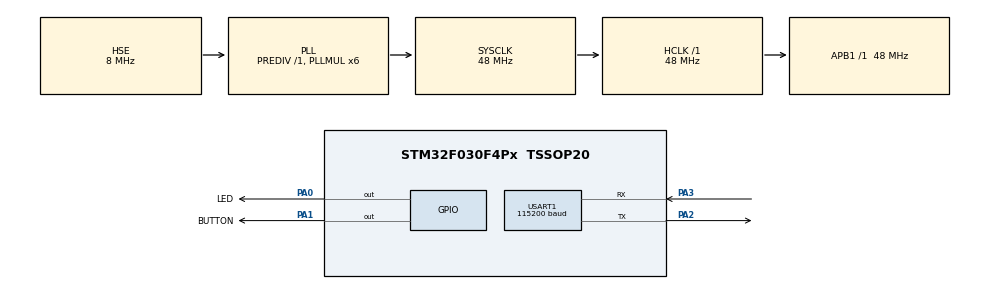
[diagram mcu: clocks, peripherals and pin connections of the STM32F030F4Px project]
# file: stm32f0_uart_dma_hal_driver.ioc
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Dma.Request0=USART1_TX
Dma.Request1=USART1_RX
Dma.USART1_RX.1.Direction=DMA_PERIPH_TO_MEMORY
Dma.USART1_RX.1.Instance=DMA1_Channel3
Dma.USART1_RX.1.MemDataAlignment=DMA_MDATAALIGN_BYTE
Dma.USART1_RX.1.MemInc=DMA_MINC_ENABLE
Dma.USART1_RX.1.Mode=DMA_NORMAL
Dma.USART1_RX.1.PeriphDataAlignment=DMA_PDATAALIGN_BYTE
Dma.USART1_RX.1.PeriphInc=DMA_PINC_DISABLE
Dma.USART1_RX.1.Priority=DMA_PRIORITY_LOW
Dma.USART1_TX.0.Direction=DMA_MEMORY_TO_PERIPH
Dma.USART1_TX.0.Instance=DMA1_Channel2
Dma.USART1_TX.0.MemDataAlignment=DMA_MDATAALIGN_BYTE
Dma.USART1_TX.0.MemInc=DMA_MINC_ENABLE
Dma.USART1_TX.0.Mode=DMA_NORMAL
Dma.USART1_TX.0.PeriphDataAlignment=DMA_PDATAALIGN_BYTE
Dma.USART1_TX.0.PeriphInc=DMA_PINC_DISABLE
Dma.USART1_TX.0.Priority=DMA_PRIORITY_LOW
Mcu.Family=STM32F0
Mcu.Name=STM32F030F4Px
Mcu.Package=TSSOP20
NVIC.DMA1_Channel2_3_IRQn=true\:0\:0\:false\:false\:true\:false\:true\:true
PA0.GPIO_Label=LED
PA0.Signal=GPIO_Output
PA1.GPIO_Label=BUTTON
PA1.Signal=GPIO_Output
PA13.Mode=Serial_Wire
PA13.Signal=SYS_SWDIO
PA14.Mode=Serial_Wire
PA14.Signal=SYS_SWCLK
PA2.Mode=Asynchronous
PA2.Signal=USART1_TX
PA3.Mode=Asynchronous
PA3.Signal=USART1_RX
PF0-OSC_IN.Mode=HSE-External-Oscillator
PF0-OSC_IN.Signal=RCC_OSC_IN
PF1-OSC_OUT.Mode=HSE-External-Oscillator
PF1-OSC_OUT.Signal=RCC_OSC_OUT
ProjectManager.HeapSize=0x200
ProjectManager.StackSize=0x400
ProjectManager.TargetToolchain=STM32CubeIDE
RCC.AHBFreq_Value=48000000
RCC.APB1Freq_Value=48000000
RCC.APB1TimFreq_Value=48000000
RCC.EnbaleCSS=true
RCC.HCLKFreq_Value=48000000
RCC.PLLMUL=RCC_PLL_MUL6
RCC.PLLSourceVirtual=RCC_PLLSOURCE_HSE
RCC.SYSCLKFreq_VALUE=48000000
RCC.SYSCLKSource=RCC_SYSCLKSOURCE_PLLCLK
USART1.BaudRate=115200
USART1.VirtualMode-Asynchronous=VM_ASYNC
board=custom

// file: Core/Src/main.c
/* USER CODE BEGIN Header */
/**
  ******************************************************************************
  * @file           : main.c
  * @brief          : Main program body
  ******************************************************************************
  * @attention
  *
  * Copyright (c) 2025 STMicroelectronics.
  * All rights reserved.
  *
  * This software is licensed under terms that can be found in the LICENSE file
  * in the root directory of this software component.
  * If no LICENSE file comes with this software, it is provided AS-IS.
  *
  ******************************************************************************
  */
/* USER CODE END Header */
#include "main.h"

/* USER CODE BEGIN Includes */
#include "stdio.h"
/* USER CODE END Includes */

UART_HandleTypeDef huart1;
DMA_HandleTypeDef hdma_usart1_tx;
DMA_HandleTypeDef hdma_usart1_rx;

void SystemClock_Config(void);
static void MX_GPIO_Init(void);
static void MX_DMA_Init(void);
static void MX_USART1_UART_Init(void);

/* USER CODE BEGIN 0 */

uint8_t txData[] = "Hello World From STM32F0!\n";

uint8_t rxData[20];

uint8_t tx_flag = 0;
uint8_t rx_flag = 0;

/* USER CODE END 0 */

int main(void)
{

  /* MCU Configuration--------------------------------------------------------*/

  /* Reset of all peripherals, Initializes the Flash interface and the Systick. */
  HAL_Init();

  /* Configure the system clock */
  SystemClock_Config();

  /* Initialize all configured peripherals */
  MX_GPIO_Init();
  MX_DMA_Init();
  MX_USART1_UART_Init();
  /* USER CODE BEGIN 2 */

  /* uart transmit with dma, buffer: txData, length: sizeof(txData) - 1 */
  HAL_UART_Transmit_DMA(&huart1, txData, sizeof(txData) - 1);

  /* uart receive with dma, buffer: rxData, length: 10 */
  HAL_UART_Receive_DMA(&huart1, rxData, 10);

  /* USER CODE END 2 */

  /* Infinite loop */
  while (1)
  {

  }
}

void SystemClock_Config(void)
{
  RCC_OscInitTypeDef RCC_OscInitStruct = {0};
  RCC_ClkInitTypeDef RCC_ClkInitStruct = {0};
  RCC_PeriphCLKInitTypeDef PeriphClkInit = {0};

  /** Initializes the RCC Oscillators according to the specified parameters
  * in the RCC_OscInitTypeDef structure.
  */
  RCC_OscInitStruct.OscillatorType = RCC_OSCILLATORTYPE_HSE;
  RCC_OscInitStruct.HSEState = RCC_HSE_ON;
  RCC_OscInitStruct.PLL.PLLState = RCC_PLL_ON;
  RCC_OscInitStruct.PLL.PLLSource = RCC_PLLSOURCE_HSE;
  RCC_OscInitStruct.PLL.PLLMUL = RCC_PLL_MUL6;
  RCC_OscInitStruct.PLL.PREDIV = RCC_PREDIV_DIV1;
  if (HAL_RCC_OscConfig(&RCC_OscInitStruct) != HAL_OK)
  {
    Error_Handler();
  }

  /** Initializes the CPU, AHB and APB buses clocks
  */
  RCC_ClkInitStruct.ClockType = RCC_CLOCKTYPE_HCLK|RCC_CLOCKTYPE_SYSCLK
                              |RCC_CLOCKTYPE_PCLK1;
  RCC_ClkInitStruct.SYSCLKSource = RCC_SYSCLKSOURCE_PLLCLK;
  RCC_ClkInitStruct.AHBCLKDivider = RCC_SYSCLK_DIV1;
  RCC_ClkInitStruct.APB1CLKDivider = RCC_HCLK_DIV1;

  if (HAL_RCC_ClockConfig(&RCC_ClkInitStruct, FLASH_LATENCY_1) != HAL_OK)
  {
    Error_Handler();
  }
  PeriphClkInit.PeriphClockSelection = RCC_PERIPHCLK_USART1;
  PeriphClkInit.Usart1ClockSelection = RCC_USART1CLKSOURCE_PCLK1;
  if (HAL_RCCEx_PeriphCLKConfig(&PeriphClkInit) != HAL_OK)
  {
    Error_Handler();
  }

  /** Enables the Clock Security System
  */
  HAL_RCC_EnableCSS();
}

static void MX_USART1_UART_Init(void)
{

  huart1.Instance = USART1;
  huart1.Init.BaudRate = 115200;
  huart1.Init.WordLength = UART_WORDLENGTH_8B;
  huart1.Init.StopBits = UART_STOPBITS_1;
  huart1.Init.Parity = UART_PARITY_NONE;
  huart1.Init.Mode = UART_MODE_TX_RX;
  huart1.Init.HwFlowCtl = UART_HWCONTROL_NONE;
  huart1.Init.OverSampling = UART_OVERSAMPLING_16;
  huart1.Init.OneBitSampling = UART_ONE_BIT_SAMPLE_DISABLE;
  huart1.AdvancedInit.AdvFeatureInit = UART_ADVFEATURE_NO_INIT;
  if (HAL_UART_Init(&huart1) != HAL_OK)
  {
    Error_Handler();
  }

}

static void MX_DMA_Init(void)
{

  /* DMA controller clock enable */
  __HAL_RCC_DMA1_CLK_ENABLE();

  /* DMA interrupt init */
  /* DMA1_Channel2_3_IRQn interrupt configuration */
  HAL_NVIC_SetPriority(DMA1_Channel2_3_IRQn, 0, 0);
  HAL_NVIC_EnableIRQ(DMA1_Channel2_3_IRQn);

}

static void MX_GPIO_Init(void)
{
  GPIO_InitTypeDef GPIO_InitStruct = {0};

  /* GPIO Ports Clock Enable */
  __HAL_RCC_GPIOF_CLK_ENABLE();
  __HAL_RCC_GPIOA_CLK_ENABLE();

  /*Configure GPIO pin Output Level */
  HAL_GPIO_WritePin(GPIOA, LED_Pin|BUTTON_Pin, GPIO_PIN_RESET);

  /*Configure GPIO pins : LED_Pin BUTTON_Pin */
  GPIO_InitStruct.Pin = LED_Pin|BUTTON_Pin;
  GPIO_InitStruct.Mode = GPIO_MODE_OUTPUT_PP;
  GPIO_InitStruct.Pull = GPIO_NOPULL;
  GPIO_InitStruct.Speed = GPIO_SPEED_FREQ_LOW;
  HAL_GPIO_Init(GPIOA, &GPIO_InitStruct);

}

void Error_Handler(void)
{
  __disable_irq();
  while (1)
  {
  }
}
